# Qorvo_SVD register map
Vendor: Qorvo Inc; Series: ARMCM4; File version: 1.0
Registers are 8-bit, read-write, reset 0x0 unless marked. A register's access mark holds for its fields unless they carry their own. Offsets are from the block's base; [hi:lo] are bit positions; {n}, {i} and the like mark numbered series.

## DMAS
Base 0x40001200
0x00 DMAS_0X00000000[0]
  [7:0] SRC_ADDR_0[0] — Start address of the source to be copied from. The address needs to match an address boundary conforming to the DMA memory access unit size (i.e. the word mode)
0x01 DMAS_0X00000000[1]
  [7:0] SRC_ADDR_0[1] — Start address of the source to be copied from. The address needs to match an address boundary conforming to the DMA memory access unit size (i.e. the word mode)
0x02 DMAS_0X00000000[2]
  [4:0] SRC_ADDR_0[2] — Start address of the source to be copied from. The address needs to match an address boundary conforming to the DMA memory access unit size (i.e. the word mode)
0x04 DMAS_0X00000004[0]
  [7:0] DEST_ADDR_0[0] — Start address of the destination to be copied to. The address needs to match an address boundary conforming to the DMA memory access unit size (i.e. the word mode)
0x05 DMAS_0X00000004[1]
  [7:0] DEST_ADDR_0[1] — Start address of the destination to be copied to. The address needs to match an address boundary conforming to the DMA memory access unit size (i.e. the word mode)
0x06 DMAS_0X00000004[2]
  [4:0] DEST_ADDR_0[2] — Start address of the destination to be copied to. The address needs to match an address boundary conforming to the DMA memory access unit size (i.e. the word mode)
0x08 DMAS_0X00000008 16-bit
  [11:0] BUFFER_SIZE_0 — Size of either the source or destination buffer_0, depending on circular_buffer_select_0. Expressed as a multiple of the DMA memory access unit. buffer_size_0=n_units-1
0x0A DMAS_0X0000000A 16-bit
  [11:0] BUFFER_ALMOST_COMPLETE_THRESHOLD_0 — Threshold to be used for generating either an almost empty or almost full interrupt, depending on circular_buffer_select_0. If SRC_BUFFER, interrupt is triggered when there are only (threshold-1) units left in the src buffer_0. If DEST_BUFFER, interrupt is triggered when there are (threshold+1) units written in the dest buffer_0.
0x0C DMAS_0X0000000C 16-bit
  [11:0] BUFFER_PTR_VALUE_0 — Pointer value to be used when triggering the different pointer sets (allows for atomic pointer set)
0x0E DMAS_0X0000000E
  [0] BUFFER_PTR_WRAP_VALUE_0 — Pointer wrap value to be used when triggering the different pointer sets (allows for atomic pointer set)
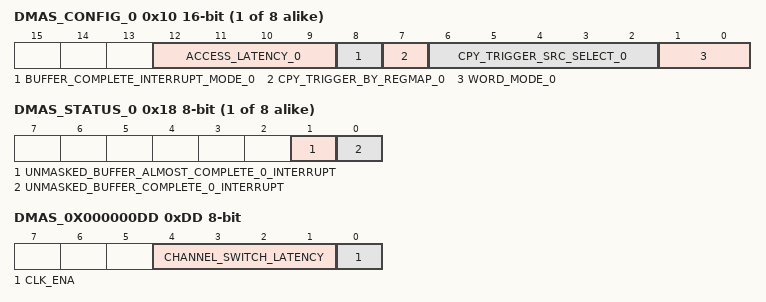
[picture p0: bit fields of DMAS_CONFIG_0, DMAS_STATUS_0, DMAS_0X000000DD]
{0x10+0x1C*i} DMAS_CONFIG_{i} 16-bit (i=0..7)
  [12:9] ACCESS_LATENCY_{i} — Minimum number of idle cycles between accesses to the same dma channel. Should be increased for slowly responding cpy_triggers.
  [8] BUFFER_COMPLETE_INTERRUPT_MODE_{i} — If set to error_mode then the buffer_complete interrupt indicates overflow/underrun conditions. Otherwise (status_mode) full/empty conditions are reported.
  [7] CPY_TRIGGER_BY_REGMAP_{i} — regmap cpy trigger_{i} overrule. The dma copy will be triggered as long as this bit is set to 1
  [6:2] CPY_TRIGGER_SRC_SELECT_{i} — Selects the slave interface that will be the source for triggering the dma copy action
  [1:0] WORD_MODE_{i} — Sets the size of the memory access unit. DMA supports 8/16/32-bit memory access. byte = 8 bits, half_word = 16 bits, word = 32 bits
0x12 DMAS_0X00000012
  [0] CPY_TRIGGER_IGNORE_BUFFER_COMPLETE_0 — When enabled, the buffer_0's completeness is ignored when triggering a dma copy action
0x13 DMAS_0X00000013
  [0] CIRCULAR_BUFFER_SELECT_0 — Selects between source and destination as circular buffer locatio.
{0x18+0x1C*i} DMAS_STATUS_{i} ro (i=0..7)
  [1] UNMASKED_BUFFER_ALMOST_COMPLETE_{i}_INTERRUPT — Indicates that the almost complete threshold has been reached, actual level depends on the circular_buffer_select_{i}. See threshold setting for more info
  [0] UNMASKED_BUFFER_COMPLETE_{i}_INTERRUPT — Refers to the selected circular buffer. In buffer_complete_interrupt_mode_{i} = error_mode overflow (for circular_buffer_select_{i} = dest_buffer) or underrun (for circular_buffer_select_{i} = src_buffer) errors are indicated. In buffer_complete_interrupt_mode_{i} = status_mode it indicates full (for circular_buffer_select_{i} = dest_buffer) or empty (for circular_buffer_select_{i} = src_buffer) status.
0x1C DMAS_0X0000001C[0]
  [7:0] SRC_ADDR_1[0] — Start address of the source to be copied from. The address needs to match an address boundary conforming to the DMA memory access unit size (i.e. the word mode)
0x1D DMAS_0X0000001C[1]
  [7:0] SRC_ADDR_1[1] — Start address of the source to be copied from. The address needs to match an address boundary conforming to the DMA memory access unit size (i.e. the word mode)
0x1E DMAS_0X0000001C[2]
  [4:0] SRC_ADDR_1[2] — Start address of the source to be copied from. The address needs to match an address boundary conforming to the DMA memory access unit size (i.e. the word mode)
0x20 DMAS_0X00000020[0]
  [7:0] DEST_ADDR_1[0] — Start address of the destination to be copied to. The address needs to match an address boundary conforming to the DMA memory access unit size (i.e. the word mode)
0x21 DMAS_0X00000020[1]
  [7:0] DEST_ADDR_1[1] — Start address of the destination to be copied to. The address needs to match an address boundary conforming to the DMA memory access unit size (i.e. the word mode)
0x22 DMAS_0X00000020[2]
  [4:0] DEST_ADDR_1[2] — Start address of the destination to be copied to. The address needs to match an address boundary conforming to the DMA memory access unit size (i.e. the word mode)
0x24 DMAS_0X00000024 16-bit
  [11:0] BUFFER_SIZE_1 — Size of either the source or destination buffer_1, depending on circular_buffer_select_1. Expressed as a multiple of the DMA memory access unit. buffer_size_1=n_units-1
0x26 DMAS_0X00000026 16-bit
  [11:0] BUFFER_ALMOST_COMPLETE_THRESHOLD_1 — Threshold to be used for generating either an almost empty or almost full interrupt, depending on circular_buffer_select_1. If SRC_BUFFER, interrupt is triggered when there are only (threshold-1) units left in the src buffer_1. If DEST_BUFFER, interrupt is triggered when there are (threshold+1) units written in the dest buffer_1.
0x28 DMAS_0X00000028 16-bit
  [11:0] BUFFER_PTR_VALUE_1 — Pointer value to be used when triggering the different pointer sets (allows for atomic pointer set)
0x2A DMAS_0X0000002A
  [0] BUFFER_PTR_WRAP_VALUE_1 — Pointer wrap value to be used when triggering the different pointer sets (allows for atomic pointer set)
0x2E DMAS_0X0000002E
  [0] CPY_TRIGGER_IGNORE_BUFFER_COMPLETE_1 — When enabled, the buffer_1's completeness is ignored when triggering a dma copy action
0x2F DMAS_0X0000002F
  [0] CIRCULAR_BUFFER_SELECT_1 — Selects between source and destination as circular buffer locatio.
0x38 DMAS_0X00000038[0]
  [7:0] SRC_ADDR_2[0] — Start address of the source to be copied from. The address needs to match an address boundary conforming to the DMA memory access unit size (i.e. the word mode)
0x39 DMAS_0X00000038[1]
  [7:0] SRC_ADDR_2[1] — Start address of the source to be copied from. The address needs to match an address boundary conforming to the DMA memory access unit size (i.e. the word mode)
0x3A DMAS_0X00000038[2]
  [4:0] SRC_ADDR_2[2] — Start address of the source to be copied from. The address needs to match an address boundary conforming to the DMA memory access unit size (i.e. the word mode)
0x3C DMAS_0X0000003C[0]
  [7:0] DEST_ADDR_2[0] — Start address of the destination to be copied to. The address needs to match an address boundary conforming to the DMA memory access unit size (i.e. the word mode)
0x3D DMAS_0X0000003C[1]
  [7:0] DEST_ADDR_2[1] — Start address of the destination to be copied to. The address needs to match an address boundary conforming to the DMA memory access unit size (i.e. the word mode)
0x3E DMAS_0X0000003C[2]
  [4:0] DEST_ADDR_2[2] — Start address of the destination to be copied to. The address needs to match an address boundary conforming to the DMA memory access unit size (i.e. the word mode)
0x40 DMAS_0X00000040 16-bit
  [11:0] BUFFER_SIZE_2 — Size of either the source or destination buffer_2, depending on circular_buffer_select_2. Expressed as a multiple of the DMA memory access unit. buffer_size_2=n_units-1
0x42 DMAS_0X00000042 16-bit
  [11:0] BUFFER_ALMOST_COMPLETE_THRESHOLD_2 — Threshold to be used for generating either an almost empty or almost full interrupt, depending on circular_buffer_select_2. If SRC_BUFFER, interrupt is triggered when there are only (threshold-1) units left in the src buffer_2. If DEST_BUFFER, interrupt is triggered when there are (threshold+1) units written in the dest buffer_2.
0x44 DMAS_0X00000044 16-bit
  [11:0] BUFFER_PTR_VALUE_2 — Pointer value to be used when triggering the different pointer sets (allows for atomic pointer set)
0x46 DMAS_0X00000046
  [0] BUFFER_PTR_WRAP_VALUE_2 — Pointer wrap value to be used when triggering the different pointer sets (allows for atomic pointer set)
0x4A DMAS_0X0000004A
  [0] CPY_TRIGGER_IGNORE_BUFFER_COMPLETE_2 — When enabled, the buffer_2's completeness is ignored when triggering a dma copy action
0x4B DMAS_0X0000004B
  [0] CIRCULAR_BUFFER_SELECT_2 — Selects between source and destination as circular buffer locatio.
0x54 DMAS_0X00000054[0]
  [7:0] SRC_ADDR_3[0] — Start address of the source to be copied from. The address needs to match an address boundary conforming to the DMA memory access unit size (i.e. the word mode)
0x55 DMAS_0X00000054[1]
  [7:0] SRC_ADDR_3[1] — Start address of the source to be copied from. The address needs to match an address boundary conforming to the DMA memory access unit size (i.e. the word mode)
0x56 DMAS_0X00000054[2]
  [4:0] SRC_ADDR_3[2] — Start address of the source to be copied from. The address needs to match an address boundary conforming to the DMA memory access unit size (i.e. the word mode)
0x58 DMAS_0X00000058[0]
  [7:0] DEST_ADDR_3[0] — Start address of the destination to be copied to. The address needs to match an address boundary conforming to the DMA memory access unit size (i.e. the word mode)
0x59 DMAS_0X00000058[1]
  [7:0] DEST_ADDR_3[1] — Start address of the destination to be copied to. The address needs to match an address boundary conforming to the DMA memory access unit size (i.e. the word mode)
0x5A DMAS_0X00000058[2]
  [4:0] DEST_ADDR_3[2] — Start address of the destination to be copied to. The address needs to match an address boundary conforming to the DMA memory access unit size (i.e. the word mode)
0x5C DMAS_0X0000005C 16-bit
  [11:0] BUFFER_SIZE_3 — Size of either the source or destination buffer_3, depending on circular_buffer_select_3. Expressed as a multiple of the DMA memory access unit. buffer_size_3=n_units-1
0x5E DMAS_0X0000005E 16-bit
  [11:0] BUFFER_ALMOST_COMPLETE_THRESHOLD_3 — Threshold to be used for generating either an almost empty or almost full interrupt, depending on circular_buffer_select_3. If SRC_BUFFER, interrupt is triggered when there are only (threshold-1) units left in the src buffer_3. If DEST_BUFFER, interrupt is triggered when there are (threshold+1) units written in the dest buffer_3.
0x60 DMAS_0X00000060 16-bit
  [11:0] BUFFER_PTR_VALUE_3 — Pointer value to be used when triggering the different pointer sets (allows for atomic pointer set)
0x62 DMAS_0X00000062
  [0] BUFFER_PTR_WRAP_VALUE_3 — Pointer wrap value to be used when triggering the different pointer sets (allows for atomic pointer set)
0x66 DMAS_0X00000066
  [0] CPY_TRIGGER_IGNORE_BUFFER_COMPLETE_3 — When enabled, the buffer_3's completeness is ignored when triggering a dma copy action
0x67 DMAS_0X00000067
  [0] CIRCULAR_BUFFER_SELECT_3 — Selects between source and destination as circular buffer locatio.
0x70 DMAS_0X00000070[0]
  [7:0] SRC_ADDR_4[0] — Start address of the source to be copied from. The address needs to match an address boundary conforming to the DMA memory access unit size (i.e. the word mode)
0x71 DMAS_0X00000070[1]
  [7:0] SRC_ADDR_4[1] — Start address of the source to be copied from. The address needs to match an address boundary conforming to the DMA memory access unit size (i.e. the word mode)
0x72 DMAS_0X00000070[2]
  [4:0] SRC_ADDR_4[2] — Start address of the source to be copied from. The address needs to match an address boundary conforming to the DMA memory access unit size (i.e. the word mode)
0x74 DMAS_0X00000074[0]
  [7:0] DEST_ADDR_4[0] — Start address of the destination to be copied to. The address needs to match an address boundary conforming to the DMA memory access unit size (i.e. the word mode)
0x75 DMAS_0X00000074[1]
  [7:0] DEST_ADDR_4[1] — Start address of the destination to be copied to. The address needs to match an address boundary conforming to the DMA memory access unit size (i.e. the word mode)
0x76 DMAS_0X00000074[2]
  [4:0] DEST_ADDR_4[2] — Start address of the destination to be copied to. The address needs to match an address boundary conforming to the DMA memory access unit size (i.e. the word mode)
0x78 DMAS_0X00000078 16-bit
  [11:0] BUFFER_SIZE_4 — Size of either the source or destination buffer_4, depending on circular_buffer_select_4. Expressed as a multiple of the DMA memory access unit. buffer_size_4=n_units-1
0x7A DMAS_0X0000007A 16-bit
  [11:0] BUFFER_ALMOST_COMPLETE_THRESHOLD_4 — Threshold to be used for generating either an almost empty or almost full interrupt, depending on circular_buffer_select_4. If SRC_BUFFER, interrupt is triggered when there are only (threshold-1) units left in the src buffer_4. If DEST_BUFFER, interrupt is triggered when there are (threshold+1) units written in the dest buffer_4.
0x7C DMAS_0X0000007C 16-bit
  [11:0] BUFFER_PTR_VALUE_4 — Pointer value to be used when triggering the different pointer sets (allows for atomic pointer set)
0x7E DMAS_0X0000007E
  [0] BUFFER_PTR_WRAP_VALUE_4 — Pointer wrap value to be used when triggering the different pointer sets (allows for atomic pointer set)
0x82 DMAS_0X00000082
  [0] CPY_TRIGGER_IGNORE_BUFFER_COMPLETE_4 — When enabled, the buffer_4's completeness is ignored when triggering a dma copy action
0x83 DMAS_0X00000083
  [0] CIRCULAR_BUFFER_SELECT_4 — Selects between source and destination as circular buffer locatio.
0x8C DMAS_0X0000008C[0]
  [7:0] SRC_ADDR_5[0] — Start address of the source to be copied from. The address needs to match an address boundary conforming to the DMA memory access unit size (i.e. the word mode)
0x8D DMAS_0X0000008C[1]
  [7:0] SRC_ADDR_5[1] — Start address of the source to be copied from. The address needs to match an address boundary conforming to the DMA memory access unit size (i.e. the word mode)
0x8E DMAS_0X0000008C[2]
  [4:0] SRC_ADDR_5[2] — Start address of the source to be copied from. The address needs to match an address boundary conforming to the DMA memory access unit size (i.e. the word mode)
0x90 DMAS_0X00000090[0]
  [7:0] DEST_ADDR_5[0] — Start address of the destination to be copied to. The address needs to match an address boundary conforming to the DMA memory access unit size (i.e. the word mode)
0x91 DMAS_0X00000090[1]
  [7:0] DEST_ADDR_5[1] — Start address of the destination to be copied to. The address needs to match an address boundary conforming to the DMA memory access unit size (i.e. the word mode)
0x92 DMAS_0X00000090[2]
  [4:0] DEST_ADDR_5[2] — Start address of the destination to be copied to. The address needs to match an address boundary conforming to the DMA memory access unit size (i.e. the word mode)
0x94 DMAS_0X00000094 16-bit
  [11:0] BUFFER_SIZE_5 — Size of either the source or destination buffer_5, depending on circular_buffer_select_5. Expressed as a multiple of the DMA memory access unit. buffer_size_5=n_units-1
0x96 DMAS_0X00000096 16-bit
  [11:0] BUFFER_ALMOST_COMPLETE_THRESHOLD_5 — Threshold to be used for generating either an almost empty or almost full interrupt, depending on circular_buffer_select_5. If SRC_BUFFER, interrupt is triggered when there are only (threshold-1) units left in the src buffer_5. If DEST_BUFFER, interrupt is triggered when there are (threshold+1) units written in the dest buffer_5.
0x98 DMAS_0X00000098 16-bit
  [11:0] BUFFER_PTR_VALUE_5 — Pointer value to be used when triggering the different pointer sets (allows for atomic pointer set)
0x9A DMAS_0X0000009A
  [0] BUFFER_PTR_WRAP_VALUE_5 — Pointer wrap value to be used when triggering the different pointer sets (allows for atomic pointer set)
0x9E DMAS_0X0000009E
  [0] CPY_TRIGGER_IGNORE_BUFFER_COMPLETE_5 — When enabled, the buffer_5's completeness is ignored when triggering a dma copy action
0x9F DMAS_0X0000009F
  [0] CIRCULAR_BUFFER_SELECT_5 — Selects between source and destination as circular buffer locatio.
0xA8 DMAS_0X000000A8[0]
  [7:0] SRC_ADDR_6[0] — Start address of the source to be copied from. The address needs to match an address boundary conforming to the DMA memory access unit size (i.e. the word mode)
0xA9 DMAS_0X000000A8[1]
  [7:0] SRC_ADDR_6[1] — Start address of the source to be copied from. The address needs to match an address boundary conforming to the DMA memory access unit size (i.e. the word mode)
0xAA DMAS_0X000000A8[2]
  [4:0] SRC_ADDR_6[2] — Start address of the source to be copied from. The address needs to match an address boundary conforming to the DMA memory access unit size (i.e. the word mode)
0xAC DMAS_0X000000AC[0]
  [7:0] DEST_ADDR_6[0] — Start address of the destination to be copied to. The address needs to match an address boundary conforming to the DMA memory access unit size (i.e. the word mode)
0xAD DMAS_0X000000AC[1]
  [7:0] DEST_ADDR_6[1] — Start address of the destination to be copied to. The address needs to match an address boundary conforming to the DMA memory access unit size (i.e. the word mode)
0xAE DMAS_0X000000AC[2]
  [4:0] DEST_ADDR_6[2] — Start address of the destination to be copied to. The address needs to match an address boundary conforming to the DMA memory access unit size (i.e. the word mode)
0xB0 DMAS_0X000000B0 16-bit
  [11:0] BUFFER_SIZE_6 — Size of either the source or destination buffer_6, depending on circular_buffer_select_6. Expressed as a multiple of the DMA memory access unit. buffer_size_6=n_units-1
0xB2 DMAS_0X000000B2 16-bit
  [11:0] BUFFER_ALMOST_COMPLETE_THRESHOLD_6 — Threshold to be used for generating either an almost empty or almost full interrupt, depending on circular_buffer_select_6. If SRC_BUFFER, interrupt is triggered when there are only (threshold-1) units left in the src buffer_6. If DEST_BUFFER, interrupt is triggered when there are (threshold+1) units written in the dest buffer_6.
0xB4 DMAS_0X000000B4 16-bit
  [11:0] BUFFER_PTR_VALUE_6 — Pointer value to be used when triggering the different pointer sets (allows for atomic pointer set)
0xB6 DMAS_0X000000B6
  [0] BUFFER_PTR_WRAP_VALUE_6 — Pointer wrap value to be used when triggering the different pointer sets (allows for atomic pointer set)
0xBA DMAS_0X000000BA
  [0] CPY_TRIGGER_IGNORE_BUFFER_COMPLETE_6 — When enabled, the buffer_6's completeness is ignored when triggering a dma copy action
0xBB DMAS_0X000000BB
  [0] CIRCULAR_BUFFER_SELECT_6 — Selects between source and destination as circular buffer locatio.
0xC4 DMAS_0X000000C4[0]
  [7:0] SRC_ADDR_7[0] — Start address of the source to be copied from. The address needs to match an address boundary conforming to the DMA memory access unit size (i.e. the word mode)
0xC5 DMAS_0X000000C4[1]
  [7:0] SRC_ADDR_7[1] — Start address of the source to be copied from. The address needs to match an address boundary conforming to the DMA memory access unit size (i.e. the word mode)
0xC6 DMAS_0X000000C4[2]
  [4:0] SRC_ADDR_7[2] — Start address of the source to be copied from. The address needs to match an address boundary conforming to the DMA memory access unit size (i.e. the word mode)
0xC8 DMAS_0X000000C8[0]
  [7:0] DEST_ADDR_7[0] — Start address of the destination to be copied to. The address needs to match an address boundary conforming to the DMA memory access unit size (i.e. the word mode)
0xC9 DMAS_0X000000C8[1]
  [7:0] DEST_ADDR_7[1] — Start address of the destination to be copied to. The address needs to match an address boundary conforming to the DMA memory access unit size (i.e. the word mode)
0xCA DMAS_0X000000C8[2]
  [4:0] DEST_ADDR_7[2] — Start address of the destination to be copied to. The address needs to match an address boundary conforming to the DMA memory access unit size (i.e. the word mode)
0xCC DMAS_0X000000CC 16-bit
  [11:0] BUFFER_SIZE_7 — Size of either the source or destination buffer_7, depending on circular_buffer_select_7. Expressed as a multiple of the DMA memory access unit. buffer_size_7=n_units-1
0xCE DMAS_0X000000CE 16-bit
  [11:0] BUFFER_ALMOST_COMPLETE_THRESHOLD_7 — Threshold to be used for generating either an almost empty or almost full interrupt, depending on circular_buffer_select_7. If SRC_BUFFER, interrupt is triggered when there are only (threshold-1) units left in the src buffer_7. If DEST_BUFFER, interrupt is triggered when there are (threshold+1) units written in the dest buffer_7.
0xD0 DMAS_0X000000D0 16-bit
  [11:0] BUFFER_PTR_VALUE_7 — Pointer value to be used when triggering the different pointer sets (allows for atomic pointer set)
0xD2 DMAS_0X000000D2
  [0] BUFFER_PTR_WRAP_VALUE_7 — Pointer wrap value to be used when triggering the different pointer sets (allows for atomic pointer set)
0xD6 DMAS_0X000000D6
  [0] CPY_TRIGGER_IGNORE_BUFFER_COMPLETE_7 — When enabled, the buffer_7's completeness is ignored when triggering a dma copy action
0xD7 DMAS_0X000000D7
  [0] CIRCULAR_BUFFER_SELECT_7 — Selects between source and destination as circular buffer locatio.
0xDD DMAS_0X000000DD
  [4:1] CHANNEL_SWITCH_LATENCY — Minimum number of idle cycles between accesses to different dma channels. Should be used to reduce the dma memory bandwidth quota.
  [0] CLK_ENA — Enables the clock to the dma block when '1'
0xDF DMAS_0X000000DF ro
  [0] UNMASKED_CPY_ERR_INTERRUPT — Indicates that a memory acces failed during dma operation. This STOPS the dma operation. Dma can only be unlocked by clearing this interrupt
